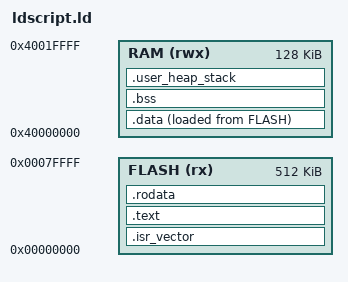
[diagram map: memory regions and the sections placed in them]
ENTRY(Reset_Handler)

_estack = ORIGIN(RAM) + LENGTH(RAM);
_Min_Heap_Size = 0x200;
_Min_Stack_Size = 0x200;

MEMORY{
    FLASH (rx) : ORIGIN = 0x0, LENGTH = 512K
    RAM (rwx) : ORIGIN = 0x40000000, LENGTH = 128K
}

SECTIONS{
    .isr_vector : {
        . = ALIGN(4);
        KEEP(*(.isr_vector))
        . = ALIGN(4);
    } > FLASH

    .text : {
        . = ALIGN(4);
        *(.text)
        *(.text*)

        KEEP(*(.init))
        KEEP(*(.fini))
        . = ALIGN(4);
        _etext = .;
    } > FLASH

    .rodata : {
        . = ALIGN(4);
        *(.rodata)
        *(.rodata*)
        . = ALIGN(4);
    } > FLASH

    _sidata = LOADADDR(.data);

    .data : {
        . = ALIGN(4);
        _sdata = .;
        *(.data)
        *(.data*)
        . = ALIGN(4);
        _edata = .;
    } > RAM AT > FLASH

    .bss : {
        . = ALIGN(4);
        _sbss = .;
        __bss_start__ = _sbss;
        *(.bss)
        *(.bss*)
        *(COMMON)

        . = ALIGN(4);
        _ebss = .;
        __bss_end__ = _ebss;
    } > RAM

    .user_heap_stack : {
        . = ALIGN(4);
        PROVIDE ( end = . );
        PROVIDE ( _end = . );
        . = . + _Min_Heap_Size;
        . = . + _Min_Stack_Size;
        . = ALIGN(4);
    } > RAM

}

